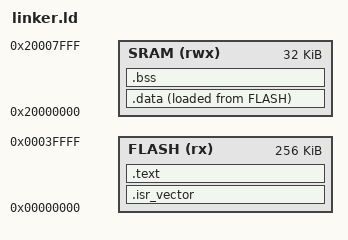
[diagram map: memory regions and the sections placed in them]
/* Reset_Handler is the first instruction executed after reset. */
ENTRY(Reset_Handler)

MEMORY
{
    FLASH (rx) : ORIGIN = 0x00000000, LENGTH = 256K
    SRAM (rwx) : ORIGIN = 0x20000000, LENGTH = 32K
}

SECTIONS
{
    .isr_vector :
    {
        KEEP(*(.isr_vector))
    } > FLASH

    .text :
    {
        . = ALIGN(4);

        *(.text)
        *(.text.*)
        *(.rodata)
        *(.rodata.*)

        . = ALIGN(4);
        _etext = .;
    } > FLASH

    .data :
    {
        . = ALIGN(4);
        _sdata = .;

        *(.data)
        *(.data.*)

        . = ALIGN(4);
        _edata = .;
    } > SRAM AT > FLASH
    _sidata = LOADADDR(.data);

    .bss :
    {
        . = ALIGN(4);
        _sbss = .;

        *(.bss)
        *(.bss.*)
        *(COMMON)

        . = ALIGN(4);
        _ebss = .;

        end = .;
        _end = .;
    } > SRAM
}

_estack = ORIGIN(SRAM) + LENGTH(SRAM);
